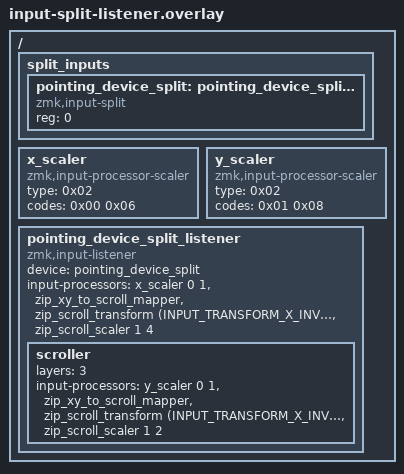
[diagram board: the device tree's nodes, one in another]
/{
    split_inputs {
        #address-cells = <1>;
        #size-cells = <0>;

        pointing_device_split: pointing_device_split@0 {
            compatible = "zmk,input-split";
            reg = <0>;
        };
    };

    /* 各軸の入力を制御するためのスケーラー定義 */
    x_scaler: x_scaler {
        compatible = "zmk,input-processor-scaler";
        #input-processor-cells = <2>;
        type = <0x02>; /* EV_REL */
        codes = <0x00 0x06>; /* X軸 / 横スクロール */
    };

    y_scaler: y_scaler {
        compatible = "zmk,input-processor-scaler";
        #input-processor-cells = <2>;
        type = <0x02>; /* EV_REL */
        codes = <0x01 0x08>; /* Y軸 / 縦スクロール */
    };

    pointing_device_split_listener: pointing_device_split_listener {
        compatible = "zmk,input-listener";
        device = <&pointing_device_split>;
        status = "okay";

        /* デフォルト：上下方向のみ (X軸方向の入力を 0倍にする) */
        input-processors = 
            <&x_scaler 0 1>,
            <&zip_xy_to_scroll_mapper>, 
            <&zip_scroll_transform (INPUT_TRANSFORM_X_INVERT)>, 
            <&zip_scroll_scaler 1 4>;

        scroller {
            layers = <3>;
            /* レイヤー3：左右方向のみ (Y軸方向の入力を 0倍にする) */
            input-processors = 
                <&y_scaler 0 1>,
                <&zip_xy_to_scroll_mapper>, 
                <&zip_scroll_transform (INPUT_TRANSFORM_X_INVERT)>, 
                <&zip_scroll_scaler 1 2>;
        };
     };
};
